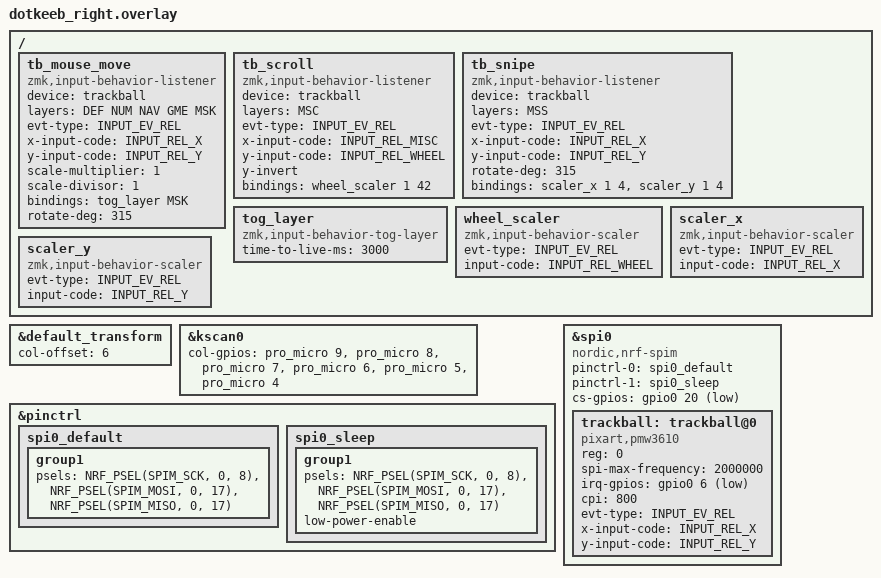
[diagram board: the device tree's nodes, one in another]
#include "dotkeeb.dtsi"
#define INPUT_EV_KEY 0x01               /**< Key event */
#define INPUT_EV_REL 0x02               /**< Relative coordinate event */
#define INPUT_EV_ABS 0x03               /**< Absolute coordinate event */
#define INPUT_EV_MSC 0x04               /**< Miscellaneous event */
#define INPUT_EV_VENDOR_START 0xf0      /**< Vendor specific event start */
#define INPUT_EV_VENDOR_STOP 0xff       /**< Vendor specific event stop */

#define INPUT_REL_X 0x00                /**< Relative X coordinate */
#define INPUT_REL_Y 0x01                /**< Relative Y coordinate */
#define INPUT_REL_WHEEL 0x08            /**< Relative wheel coordinate */
#define INPUT_REL_HWHEEL 0x06           /**< Relative horizontal wheel coordinate */
#define INPUT_REL_MISC 0x09             /**< Relative misc coordinate */

#define DEF 0 // default layer
#define GME 1 // game layer
#define NUM 2 // secondary num layer
#define NAV 3 // navigation layer
#define MSK 4 // mouse key layer
#define MSC 6 // mouse scroll layer
#define MSS 7 // mouse snipe layer

&default_transform { 
    col-offset = <6>;
};

&kscan0 {
    col-gpios
        = <&pro_micro 9 GPIO_ACTIVE_HIGH> // col1
        , <&pro_micro 8 GPIO_ACTIVE_HIGH> // col2
        , <&pro_micro 7 GPIO_ACTIVE_HIGH> // col3
        , <&pro_micro 6 GPIO_ACTIVE_HIGH> // col4
        , <&pro_micro 5 GPIO_ACTIVE_HIGH> // col5
        , <&pro_micro 4 GPIO_ACTIVE_HIGH> // col6
        ;
};

&pinctrl {
    spi0_default: spi0_default {
        group1 {
            psels = <NRF_PSEL(SPIM_SCK, 0, 8)>,
                <NRF_PSEL(SPIM_MOSI, 0, 17)>,
                <NRF_PSEL(SPIM_MISO, 0, 17)>;
        };
    };

    spi0_sleep: spi0_sleep {
        group1 {
            psels = <NRF_PSEL(SPIM_SCK, 0, 8)>,
                <NRF_PSEL(SPIM_MOSI, 0, 17)>,
                <NRF_PSEL(SPIM_MISO, 0, 17)>;
            low-power-enable;
        };
    };
};

&spi0 {
    status = "okay";
    compatible = "nordic,nrf-spim";
    pinctrl-0 = <&spi0_default>;
    pinctrl-1 = <&spi0_sleep>;
    pinctrl-names = "default", "sleep";
    cs-gpios = <&gpio0 20 GPIO_ACTIVE_LOW>;

    trackball: trackball@0 {
        status = "okay";
        compatible = "pixart,pmw3610";
        reg = <0>;
        spi-max-frequency = <2000000>;
        irq-gpios = <&gpio0 6 (GPIO_ACTIVE_LOW | GPIO_PULL_UP)>;
        cpi = <800>;
        evt-type = <INPUT_EV_REL>;
        x-input-code = <INPUT_REL_X>;
        y-input-code = <INPUT_REL_Y>;
    };
};

/ {
  tb_mouse_move {
    compatible = "zmk,input-behavior-listener";
    device = <&trackball>;

    // Enable on all layers apart from scroll and snipe
    layers = <DEF NUM NAV GME MSK>;

    evt-type = <INPUT_EV_REL>;
    x-input-code = <INPUT_REL_X>;
    y-input-code = <INPUT_REL_Y>;
    scale-multiplier = <1>;
    scale-divisor = <1>;

    // Behavior to toggle the mouse key layer on trackball movement
    bindings = <&tog_layer MSK>;

    rotate-deg = <315>;
    /* NOTE 1: This settings do not compitable with y-invert and x-invert */
    /* NOTE 2: Floating point computation requires alot of ram. */
    /*         This feature will cuase stackove flow with CONFIG_ZMK_USB_LOGGING=y */
  };

  /* Switch to Scroll mode on MSC layer */
  tb_scroll {
    compatible = "zmk,input-behavior-listener";
    device = <&trackball>;
    layers = <MSC>;
    evt-type = <INPUT_EV_REL>;
    
    x-input-code = <INPUT_REL_MISC>;
    y-input-code = <INPUT_REL_WHEEL>;

    y-invert;
    bindings = <&wheel_scaler 1 42>;
  };

 /* Swtich to "Snipe" mode (lowers sensitivity) on MSS layer */ 
  tb_snipe {
    compatible = "zmk,input-behavior-listener";
    device = <&trackball>;
    layers = <MSS>;
    evt-type = <INPUT_EV_REL>;
    
    x-input-code = <INPUT_REL_X>;
    y-input-code = <INPUT_REL_Y>;
    
    rotate-deg = <315>;

    /* Reduce Sensitivity by 1/4 */
    bindings = <&scaler_x 1 4>, <&scaler_y 1 4>;
  };

  /* Timeout for automatic mouse key layer */
  tog_layer: tog_layer {
    compatible = "zmk,input-behavior-tog-layer";
    #binding-cells = <1>;
    time-to-live-ms = <3000>;
  };

  /* Scaler for scroll wheel */
  wheel_scaler: wheel_scaler {
    compatible = "zmk,input-behavior-scaler";
    #binding-cells = <2>;
    evt-type = <INPUT_EV_REL>;
    input-code = <INPUT_REL_WHEEL>;
  };

  // Scaler for x and y-axis movement. Used for snipe mode
  scaler_x: scaler_x {
    compatible = "zmk,input-behavior-scaler";
    #binding-cells = <2>;
    evt-type = <INPUT_EV_REL>;
    input-code = <INPUT_REL_X>;
  };
  scaler_y: scaler_y {
    compatible = "zmk,input-behavior-scaler";
    #binding-cells = <2>;
    evt-type = <INPUT_EV_REL>;
    input-code = <INPUT_REL_Y>;
  };
};

